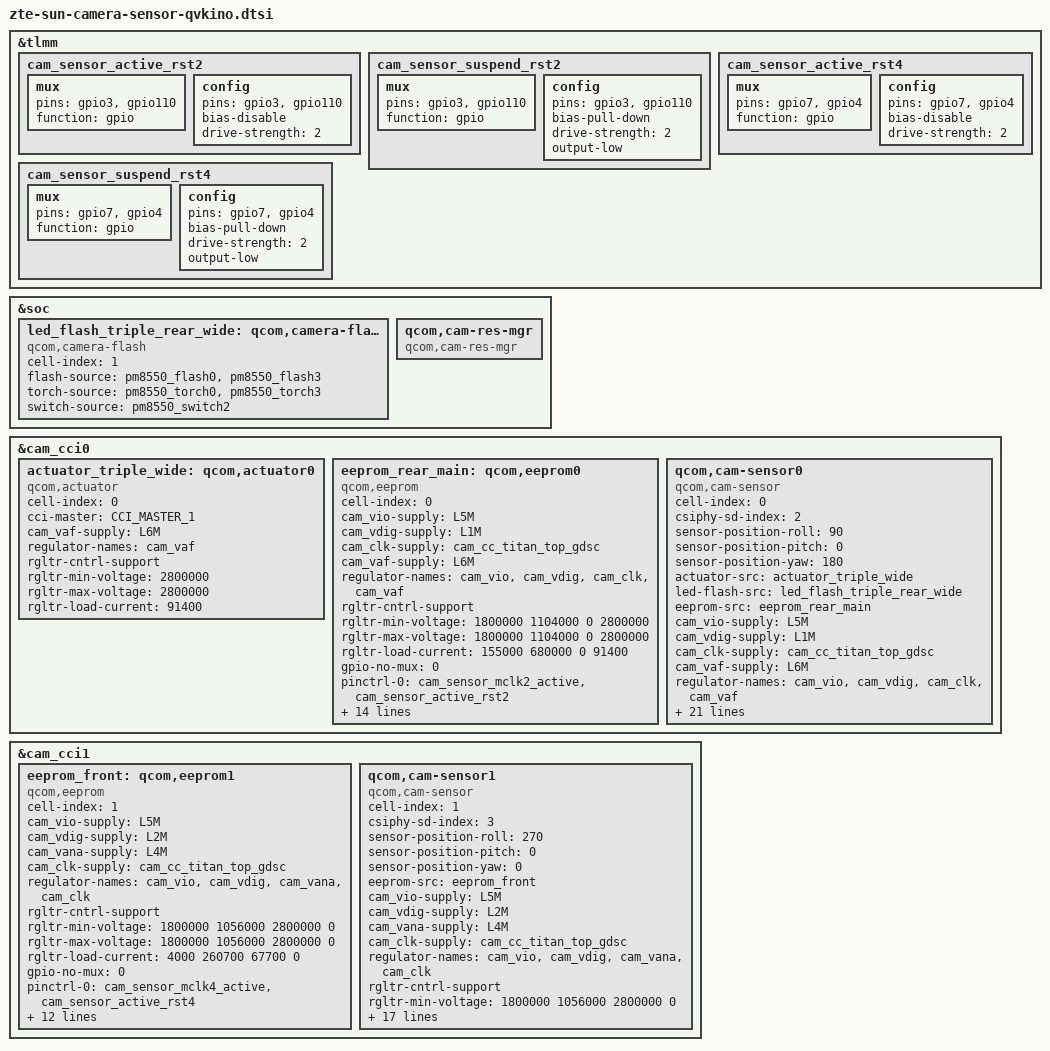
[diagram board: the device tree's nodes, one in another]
#include <dt-bindings/msm-camera.h>
&tlmm {
	cam_sensor_active_rst2: cam_sensor_active_rst2 {
		/* RESET 2 MAIN SENSOR*/
		mux {
			pins = "gpio3", "gpio110";
			function = "gpio";
		};

		config {
			pins = "gpio3", "gpio110";
			bias-disable; /* No PULL */
			drive-strength = <2>; /* 2 MA */
		};
	};

	cam_sensor_suspend_rst2: cam_sensor_suspend_rst2 {
		/* RESET 2 MAIN SENSOR*/
		mux {
			pins = "gpio3", "gpio110";
			function = "gpio";
		};

		config {
			pins = "gpio3", "gpio110";
			bias-pull-down; /* PULL DOWN */
			drive-strength = <2>; /* 2 MA */
			output-low;
		};
	};

	cam_sensor_active_rst4: cam_sensor_active_rst4 {
		/* RESET 4 FRONT SENSOR*/
		mux {
			pins = "gpio7", "gpio4";
			function = "gpio";
		};

		config {
			pins = "gpio7", "gpio4";
			bias-disable; /* No PULL */
			drive-strength = <2>; /* 2 MA */
		};
	};

	cam_sensor_suspend_rst4: cam_sensor_suspend_rst4 {
		/* RESET 4 FRONT SENSOR*/
		mux {
			pins = "gpio7", "gpio4";
			function = "gpio";
		};

		config {
			pins = "gpio7", "gpio4";
			bias-pull-down; /* PULL DOWN */
			drive-strength = <2>; /* 2 MA */
			output-low;
		};
	};
};

&soc {
	led_flash_triple_rear_wide: qcom,camera-flash1 {
		cell-index = <1>;
		compatible = "qcom,camera-flash";
		flash-source = <&pm8550_flash0 &pm8550_flash3>;
		torch-source = <&pm8550_torch0 &pm8550_torch3>;
		switch-source = <&pm8550_switch2>;
		status = "ok";
	};

	qcom,cam-res-mgr {
		compatible = "qcom,cam-res-mgr";
		status = "ok";
	};
};

&cam_cci0 {
	actuator_triple_wide: qcom,actuator0 {
		cell-index = <0>;
		compatible = "qcom,actuator";
		cci-master = <CCI_MASTER_1>;
		cam_vaf-supply = <&L6M>;
		regulator-names = "cam_vaf";
		rgltr-cntrl-support;
		rgltr-min-voltage = <2800000>;
		rgltr-max-voltage = <2800000>;
		rgltr-load-current = <91400>;
	};

	eeprom_rear_main: qcom,eeprom0 {
		cell-index = <0>;
		compatible = "qcom,eeprom";
		cam_vio-supply = <&L5M>;
		cam_vdig-supply = <&L1M>;
		cam_clk-supply = <&cam_cc_titan_top_gdsc>;
        cam_vaf-supply = <&L6M>;
		regulator-names = "cam_vio", "cam_vdig", "cam_clk", "cam_vaf";
		rgltr-cntrl-support;
		rgltr-min-voltage = <1800000 1104000 0 2800000>;
		rgltr-max-voltage = <1800000 1104000 0 2800000>;
		rgltr-load-current = <155000 680000 0 91400>;
		gpio-no-mux = <0>;
		pinctrl-names = "cam_default", "cam_suspend";
		pinctrl-0 = <&cam_sensor_mclk2_active
			&cam_sensor_active_rst2>;
		pinctrl-1 = <&cam_sensor_mclk2_suspend
			&cam_sensor_suspend_rst2>;
		gpios = <&tlmm 91 0>,
			<&tlmm 3 0>,
			<&tlmm 110 0>;
		gpio-reset = <1>;
		gpio-custom1 = <2>;
		gpio-req-tbl-num = <0 1 2>;
		gpio-req-tbl-flags = <1 0 0>;
		gpio-req-tbl-label = "CAMIF_MCLK2",
					"CAM_RESET2",
					"CAM_VANA1";
		cci-master = <CCI_MASTER_1>;
		clocks = <&cambistmclkcc CAM_BIST_MCLK_CC_MCLK2_CLK>;
		clock-names = "cam_clk";
		clock-cntl-level = "nominal";
		clock-rates = <24000000>;
		status = "ok";
	};

	qcom,cam-sensor0 {
		cell-index = <0>;
		compatible = "qcom,cam-sensor";
		csiphy-sd-index = <2>;
		sensor-position-roll = <90>;
		sensor-position-pitch = <0>;
		sensor-position-yaw = <180>;
        actuator-src = <&actuator_triple_wide>;
		led-flash-src = <&led_flash_triple_rear_wide>;
        eeprom-src = <&eeprom_rear_main>;
		cam_vio-supply = <&L5M>;
		cam_vdig-supply = <&L1M>;
		cam_clk-supply = <&cam_cc_titan_top_gdsc>;
        cam_vaf-supply = <&L6M>;
		regulator-names = "cam_vio", "cam_vdig", "cam_clk", "cam_vaf";
		rgltr-cntrl-support;
		rgltr-min-voltage = <1800000 1104000 0 2800000>;
		rgltr-max-voltage = <1800000 1104000 0 2800000>;
		rgltr-load-current = <155000 680000 0 91400>;
		gpio-no-mux = <0>;
		pinctrl-names = "cam_default", "cam_suspend";
		pinctrl-0 = <&cam_sensor_mclk2_active
			&cam_sensor_active_rst2>;
		pinctrl-1 = <&cam_sensor_mclk2_suspend
			&cam_sensor_suspend_rst2>;
		gpios = <&tlmm 91 0>,
			<&tlmm 3 0>,
			<&tlmm 110 0>;
		gpio-reset = <1>;
		gpio-custom1 = <2>;
		gpio-req-tbl-num = <0 1 2>;
		gpio-req-tbl-flags = <1 0 0>;
		gpio-req-tbl-label = "CAMIF_MCLK2",
					"CAM_RESET2",
					"CAM_VANA1";
		cci-master = <CCI_MASTER_1>;
		clocks = <&cambistmclkcc CAM_BIST_MCLK_CC_MCLK2_CLK>;
		clock-names = "cam_clk";
		clock-cntl-level = "nominal";
		clock-rates = <24000000>;
		status = "ok";
	};
};

&cam_cci1 {
	eeprom_front: qcom,eeprom1 {
		cell-index = <1>;
		compatible = "qcom,eeprom";
		cam_vio-supply = <&L5M>;
		cam_vdig-supply = <&L2M>;
		cam_vana-supply = <&L4M>;
		cam_clk-supply = <&cam_cc_titan_top_gdsc>;
		regulator-names = "cam_vio", "cam_vdig", "cam_vana", "cam_clk";
		rgltr-cntrl-support;
		rgltr-min-voltage = <1800000 1056000 2800000 0>;
		rgltr-max-voltage = <1800000 1056000 2800000 0>;
		rgltr-load-current = <4000 260700 67700 0>;
		gpio-no-mux = <0>;
		pinctrl-names = "cam_default", "cam_suspend";
		pinctrl-0 = <&cam_sensor_mclk4_active
				 &cam_sensor_active_rst4>;
		pinctrl-1 = <&cam_sensor_mclk4_suspend
				 &cam_sensor_suspend_rst4>;
		gpios = <&tlmm 93 0>,
			<&tlmm 7 0>,
			<&tlmm 4 0>;
		gpio-reset = <1>;
		gpio-req-tbl-num = <0 1>;
		gpio-req-tbl-flags = <1 0>;
		gpio-req-tbl-label = "CAMIF_MCLK4",
					"CAM_RESET4";
		cci-master = <CCI_MASTER_0>;
		clocks = <&cambistmclkcc CAM_BIST_MCLK_CC_MCLK4_CLK>;
		clock-names = "cam_clk";
		clock-cntl-level = "nominal";
		clock-rates = <24000000>;
		status = "ok";
	};

	qcom,cam-sensor1 {
		cell-index = <1>;
		compatible = "qcom,cam-sensor";
		csiphy-sd-index = <3>;
		sensor-position-roll = <270>;
		sensor-position-pitch = <0>;
		sensor-position-yaw = <0>;
        eeprom-src = <&eeprom_front>;
		cam_vio-supply = <&L5M>;
		cam_vdig-supply = <&L2M>;
		cam_vana-supply = <&L4M>;
		cam_clk-supply = <&cam_cc_titan_top_gdsc>;
		regulator-names = "cam_vio", "cam_vdig", "cam_vana", "cam_clk";
		rgltr-cntrl-support;
		rgltr-min-voltage = <1800000 1056000 2800000 0>;
		rgltr-max-voltage = <1800000 1056000 2800000 0>;
		rgltr-load-current = <4000 260700 67700 0>;
		gpio-no-mux = <0>;
		pinctrl-names = "cam_default", "cam_suspend";
		pinctrl-0 = <&cam_sensor_mclk4_active
				 &cam_sensor_active_rst4>;
		pinctrl-1 = <&cam_sensor_mclk4_suspend
				 &cam_sensor_suspend_rst4>;
		gpios = <&tlmm 93 0>,
			<&tlmm 7 0>,
			<&tlmm 4 0>;
		gpio-reset = <1>;
		gpio-req-tbl-num = <0 1>;
		gpio-req-tbl-flags = <1 0>;
		gpio-req-tbl-label = "CAMIF_MCLK4",
					"CAM_RESET4";
		cci-master = <CCI_MASTER_0>;
		clocks = <&cambistmclkcc CAM_BIST_MCLK_CC_MCLK4_CLK>;
		clock-names = "cam_clk";
		clock-cntl-level = "nominal";
		clock-rates = <24000000>;
		status = "ok";
	};
};
